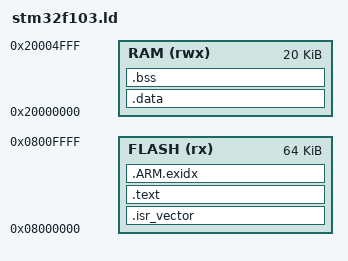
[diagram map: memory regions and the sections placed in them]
ENTRY(Reset_Handler)

MEMORY
{
  FLASH (rx) : ORIGIN = 0x08000000, LENGTH = 64K
  RAM   (rwx): ORIGIN = 0x20000000, LENGTH = 20K
}

_estack = ORIGIN(RAM) + LENGTH(RAM);

SECTIONS
{
  .isr_vector :
  {
    KEEP(*(.isr_vector))
  } > FLASH

  .text :
  {
    *(.text*)
    *(.rodata*)
    _etext = .;
  } > FLASH

  .ARM.exidx : {
    *(.ARM.exidx*)
  } > FLASH

  .data : 
  {
    _sdata = .;
    *(.data*)
    _edata = .;
  } > RAM

  .bss :
  {
    _sbss = .;
    *(.bss*)
    *(COMMON)
    _ebss = .;
  } > RAM

  /* Two lines below are newlu added*/
  end = .;
  _end = .;
  __end__ = .;
}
